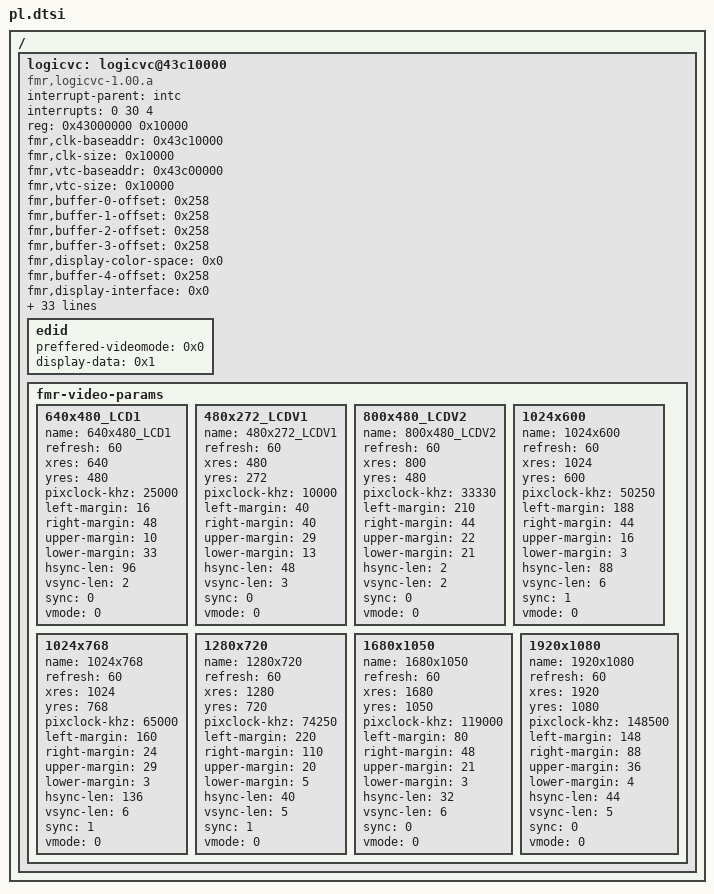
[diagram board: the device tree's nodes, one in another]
/*
 * CAUTION: This file is automatically generated by Xilinx.
 * Version:  
 * Today is: Fri Mar  6 01:02:46 2020
 */


// / {
// 	amba_pl: amba_pl {
// 		#address-cells = <1>;
// 		#size-cells = <1>;
// 		compatible = "simple-bus";
// 		ranges ;
// 		axi_vdma_0: dma@43000000 {
// 			#dma-cells = <1>;
// 			clock-names = "s_axi_lite_aclk", "m_axi_mm2s_aclk", "m_axis_mm2s_aclk";
// 			clocks = <&clkc 15>, <&clkc 16>, <&clkc 16>;
// 			compatible = "xlnx,axi-vdma-6.3", "xlnx,axi-vdma-1.00.a";
// 			interrupt-names = "mm2s_introut";
// 			interrupt-parent = <&intc>;
// 			interrupts = <0 30 4>;
// 			reg = <0x43000000 0x10000>;
// 			xlnx,addrwidth = <0x20>;
// 			xlnx,flush-fsync = <0x1>;
// 			xlnx,num-fstores = <0x1>;
// 			dma-channel@43000000 {
// 				compatible = "xlnx,axi-vdma-mm2s-channel";
// 				interrupts = <0 30 4>;
// 				xlnx,datawidth = <0x20>;
// 				xlnx,device-id = <0x0>;
// 			};
// 		};
// 		v_tc_0: v_tc@43c00000 {
// 			clock-names = "clk", "s_axi_aclk";
// 			clocks = <&misc_clk_0>, <&clkc 15>;
// 			compatible = "xlnx,v-tc-6.1", "xlnx,v-tc-6.1";
// 			interrupt-names = "irq";
// 			interrupt-parent = <&intc>;
// 			interrupts = <0 31 4>;
// 			reg = <0x43c00000 0x10000>;
// 			xlnx,generator ;
// 		};
// 		misc_clk_0: misc_clk_0 {
// 			#clock-cells = <0>;
// 			clock-frequency = <148500000>;
// 			compatible = "fixed-clock";
// 		};
// 	};
// };


/ {
	logicvc: logicvc@43c10000 {
		compatible = "fmr,logicvc-1.00.a";
		interrupt-parent = <&intc>;
		interrupts = <0 30 4>;
		reg = <0x43000000 0x10000>;
		fmr,clk-baseaddr = <0x43c10000>;
		fmr,clk-size = <0x10000>;
		fmr,vtc-baseaddr = <0x43c00000>; 
		fmr,vtc-size = <0x10000>; 
		fmr,buffer-0-offset = <0x258>;
		fmr,buffer-1-offset = <0x258>;
		fmr,buffer-2-offset = <0x258>;
		fmr,buffer-3-offset = <0x258>;
		//xlnx,buffer-4-offset = <0x438>;
		//xlnx,display-color-space = <0x0>;	//RGB
		//fmr,display-color-space = <0x1>; 	//YCbCr
		fmr,display-color-space = <0x0>; 	//RGB
		fmr,buffer-4-offset = <0x258>;		
		fmr,display-interface = <0x0>;
		fmr,layer-0-alpha-mode = <0x1>;
		fmr,layer-0-data-width = <0x18>;
		fmr,layer-0-offset = <0x0>;		//0x1c7a
		fmr,layer-0-type = <0x0>;
		fmr,layer-1-alpha-mode = <0x0>;
		fmr,layer-1-data-width = <0x18>;
		fmr,layer-1-offset = <0xfd2>;
		fmr,layer-1-type = <0x0>;
		fmr,layer-2-alpha-mode = <0x0>;
		fmr,layer-2-data-width = <0x18>;
		fmr,layer-2-offset = <0x0>;
		fmr,layer-2-type = <0x0>;
		fmr,layer-3-alpha-mode = <0x3>;
		fmr,layer-3-data-width = <0x8>;
		fmr,layer-3-offset = <0x32a0>;
		fmr,layer-3-type = <0x0>;
		fmr,layer-4-alpha-mode = <0x0>;
		fmr,layer-4-data-width = <0x18>;
		fmr,layer-4-offset = <0x2000>;
		fmr,layer-4-type = <0x0>;
		fmr,num-of-layers = <0x1>;
		fmr,readable-regs = <0x1>;
		fmr,row-stride = <0x400>;
		fmr,vmem-baseaddr = <0x30000000>;	//x3C000000
		fmr,vmem-highaddr = <0x3FFFFFFF>;
		pixel-clock-source = <2>;
		pixel-data-invert = <0>;
		pixel-clock-active-high = <0>;
		pixel-component-format = "ARGB";
		pixel-component-layer = <0x1 0x2 0x3>;
		fmr,use-background = <0x0>;
		active-layer = <0>;
		//videomode = "800x480_LCDV2";
		videomode = "1024x600";
		edid {
			preffered-videomode = <0x0>;
			display-data = <0x1>;
		};

		fmr-video-params {
			640x480_LCD1{
				name = "640x480_LCD1";
				//pwr_en = <&gpio0 114 1>;
				//bl_en = <&gpio0 115 1>;			
				refresh = <60>;
				xres = <640>;
				yres = <480>;
				pixclock-khz = <25000>;
				left-margin = <16>;
				right-margin = <48>;
				upper-margin = <10>;
				lower-margin = <33>;
				hsync-len = <96>;
				vsync-len = <2>;
				sync = <0>;
				vmode = <0>;
			};
			480x272_LCDV1{
				name = "480x272_LCDV1";
				//pwr_en = <&gpio0 114 1>;
				//bl_en = <&gpio0 115 1>;			
				refresh = <60>;
				xres = <480>;
				yres = <272>;
				pixclock-khz = <10000>;
				left-margin = <40>;
				right-margin = <40>;
				upper-margin = <29>;
				lower-margin = <13>;
				hsync-len = <48>;
				vsync-len = <3>;
				sync = <0>;
				vmode = <0>;
			};
			800x480_LCDV2 {
				name = "800x480_LCDV2";
				//pwr_en = <&gpio0 114 1>;
				//bl_en = <&gpio0 115 1>;	
				refresh = <60>;
				xres = <800>;
				yres = <480>;
				pixclock-khz = <33330>;
				left-margin = <210>;
				right-margin = <44>;
				upper-margin = <22>;
				lower-margin = <21>;
				hsync-len = <2>;
				vsync-len = <2>;
				sync = <0>;
				vmode = <0>;
			};
            1024x600 {
                name = "1024x600";
                refresh = <60>;
                xres = <1024>;
                yres = <600>;
                pixclock-khz = <50250>;
                left-margin = <188>;
                right-margin = <44>;
                upper-margin = <16>;
                lower-margin = <3>;
                hsync-len = <88>;
                vsync-len = <6>;
                sync = <1>;
                vmode = <0>;
            };
			1024x768 {
				name = "1024x768";
				refresh = <60>;
				xres = <1024>;
				yres = <768>;
				pixclock-khz = <65000>;
				left-margin = <160>;
				right-margin = <24>;
				upper-margin = <29>;
				lower-margin = <3>;
				hsync-len = <136>;
				vsync-len = <6>;
				sync = <1>;
				vmode = <0>;
			};
			1280x720 {
				name = "1280x720";
				refresh = <60>;
				xres = <1280>;
				yres = <720>;
				pixclock-khz = <74250>;
				left-margin = <220>;
				right-margin = <110>;
				upper-margin = <20>;
				lower-margin = <5>;
				hsync-len = <40>;
				vsync-len = <5>;
				sync = <1>;
				vmode = <0>;
			};
			1680x1050 {
				name = "1680x1050";
				refresh = <60>;
				xres = <1680>;
				yres = <1050>;
				pixclock-khz = <119000>;
				left-margin = <80>;
				right-margin = <48>;
				upper-margin = <21>;
				lower-margin = <3>;
				hsync-len = <32>;
				vsync-len = <6>;
				sync = <0>;
				vmode = <0>;
			};
			1920x1080 {
				name = "1920x1080";
				refresh = <60>;
				xres = <1920>;
				yres = <1080>;
				pixclock-khz = <148500>;
				left-margin = <148>;
				right-margin = <88>;
				upper-margin = <36>;
				lower-margin = <4>;
				hsync-len = <44>;
				vsync-len = <5>;
				sync = <0>;
				vmode = <0>;
			};
		};
	};
};
